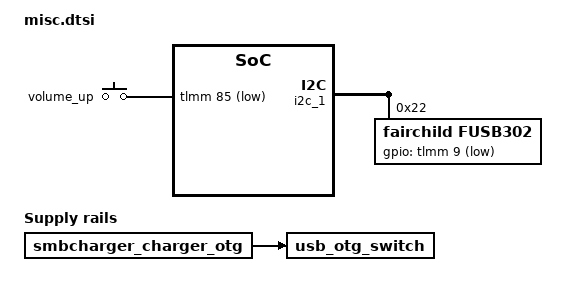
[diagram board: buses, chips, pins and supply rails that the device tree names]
/* Copyright (c) 2018, Motorola Mobility Inc. All rights reserved.
 *
 * This program is free software; you can redistribute it and/or modify
 * it under the terms of the GNU General Public License version 2 and
 * only version 2 as published by the Free Software Foundation.
 *
 * This program is distributed in the hope that it will be useful,
 * but WITHOUT ANY WARRANTY; without even the implied warranty of
 * MERCHANTABILITY or FITNESS FOR A PARTICULAR PURPOSE.  See the
 * GNU General Public License for more details.
 */

&i2c_1 {
	fusb302@22 {
		compatible = "fairchild,fusb302";
		reg = <0x22>;
		gpios = <&tlmm 9 1>; /* FUSB302_INT_N, in */
		fusb,gpio-labels = "gpio_fusb_int_n";
		pinctrl-names = "default", "active";
		pinctrl-0 = <&fusb302_int_default>;
		pinctrl-1 = <&fusb302_int_active>;
	};
};

&pm8953_typec {
	status = "disabled";
};

&soc {
	gpio_keys {
		compatible = "gpio-keys";
		input-name = "gpio-keys";
		pinctrl-names = "tlmm_gpio_key_active","tlmm_gpio_key_suspend";
		pinctrl-0 = <&gpio_key>;
		pinctrl-1 = <&gpio_key>;

		vol_up {
			label = "volume_up";
			gpios = <&tlmm 85 0x1>;
			linux,input-type = <1>;
			linux,code = <115>;
			gpio-key,wakeup;
			debounce-interval = <15>;
		};
	};

	usb_otg_switch: usb-otg-switch {
		compatible = "regulator-fixed";
		regulator-name = "usb_otg_vreg";
		vin-supply = <&smbcharger_charger_otg>;
		enable-active-high;
		status = "okay";
	};
};

/ {
	utags {
		compatible = "mmi,utags";
		mmi,main-utags = "/dev/block/bootdevice/by-name/utags";
		mmi,backup-utags = "/dev/block/bootdevice/by-name/utagsBackup";
	};

	hw {
		compatible = "mmi,utags";
		mmi,dir-name = "hw";
		mmi,main-utags = "/dev/block/bootdevice/by-name/hw";
	};
};
